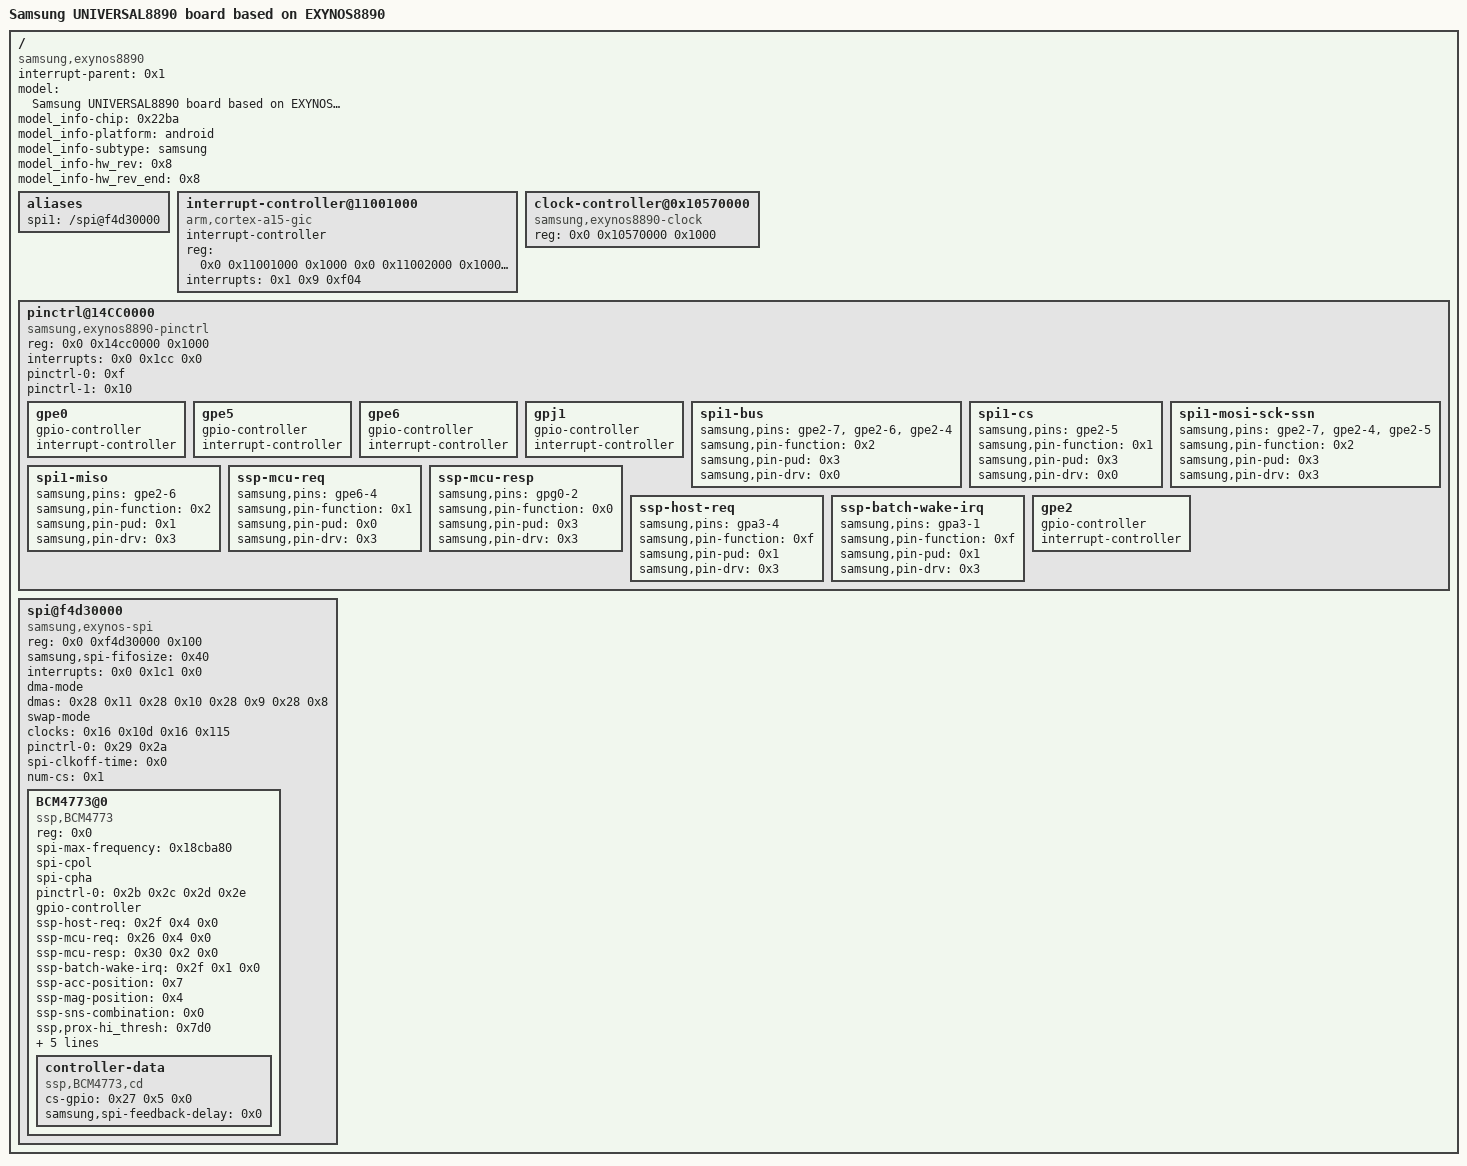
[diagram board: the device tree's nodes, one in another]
/dts-v1/;

/ {
        compatible = "samsung,exynos8890", "samsung,UNIVERSAL8890";
	interrupt-parent = <0x1>;
	#address-cells = <0x2>;
	#size-cells = <0x1>;
	model = "Samsung UNIVERSAL8890 board based on EXYNOS8890";
	model_info-chip = <0x22ba>;
	model_info-platform = "android";
	model_info-subtype = "samsung";
	model_info-hw_rev = <0x8>;
	model_info-hw_rev_end = <0x8>;

	aliases {
		//spi1 = "/spi@14d30000";
		spi1 = "/spi@f4d30000";
	};

	interrupt-controller@11001000 {
		compatible = "arm,cortex-a15-gic", "arm,cortex-a9-gic";
		#interrupt-cells = <0x3>;
		#address-cells = <0x0>;
		interrupt-controller;
		reg = <0x0 0x11001000 0x1000 0x0 0x11002000 0x1000 0x0 0x11004000 0x2000 0x0 0x11006000 0x2000>;
		interrupts = <0x1 0x9 0xf04>;
		linux,phandle = <0x1>;
		phandle = <0x1>;
	};

	clock-controller@0x10570000 {
		compatible = "samsung,exynos8890-clock";
		reg = <0x0 0x10570000 0x1000>;
		#clock-cells = <0x1>;
		linux,phandle = <0x16>;
		phandle = <0x16>;
	};

	pinctrl@14CC0000 {
		compatible = "samsung,exynos8890-pinctrl";
		reg = <0x0 0x14cc0000 0x1000>;
		interrupts = <0x0 0x1cc 0x0>;
		pinctrl-names = "default", "sleep";
		pinctrl-0 = <0xf>;
		pinctrl-1 = <0x10>;

		gpe0 {
			gpio-controller;
			#gpio-cells = <0x2>;
			interrupt-controller;
			#interrupt-cells = <0x2>;
		};

		gpe5 {
			gpio-controller;
			#gpio-cells = <0x2>;
			interrupt-controller;
			#interrupt-cells = <0x2>;
			linux,phandle = <0x5b>;
			phandle = <0x5b>;
		};

		gpe6 {
			gpio-controller;
			#gpio-cells = <0x2>;
			interrupt-controller;
			#interrupt-cells = <0x2>;
			linux,phandle = <0x26>;
			phandle = <0x26>;
		};

		gpj1 {
			gpio-controller;
			#gpio-cells = <0x2>;
			interrupt-controller;
			#interrupt-cells = <0x2>;
			linux,phandle = <0x96>;
			phandle = <0x96>;
		};

		spi1-bus {
			samsung,pins = "gpe2-7", "gpe2-6", "gpe2-4";
			samsung,pin-function = <0x2>;
			samsung,pin-pud = <0x3>;
			samsung,pin-drv = <0x0>;
		};

		spi1-cs {
			samsung,pins = "gpe2-5";
			samsung,pin-function = <0x1>;
			samsung,pin-pud = <0x3>;
			samsung,pin-drv = <0x0>;
		};

		spi1-mosi-sck-ssn {
			samsung,pins = "gpe2-7", "gpe2-4", "gpe2-5";
			samsung,pin-function = <0x2>;
			samsung,pin-pud = <0x3>;
			samsung,pin-drv = <0x3>;
			linux,phandle = <0x29>;
			phandle = <0x29>;
		};
	
		spi1-miso {
			samsung,pins = "gpe2-6";
			samsung,pin-function = <0x2>;
			samsung,pin-pud = <0x1>;
			samsung,pin-drv = <0x3>;
			linux,phandle = <0x2a>;
			phandle = <0x2a>;
		};

		ssp-mcu-req {
			samsung,pins = "gpe6-4";
			samsung,pin-function = <0x1>;
			samsung,pin-pud = <0x0>;
			samsung,pin-drv = <0x3>;
			linux,phandle = <0x2c>;
			phandle = <0x2c>;
		};

		ssp-mcu-resp {
			samsung,pins = "gpg0-2";
			samsung,pin-function = <0x0>;
			samsung,pin-pud = <0x3>;
			samsung,pin-drv = <0x3>;
			linux,phandle = <0x2d>;
			phandle = <0x2d>;
		};

		ssp-host-req {
			samsung,pins = "gpa3-4";
			samsung,pin-function = <0xf>;
			samsung,pin-pud = <0x1>;
			samsung,pin-drv = <0x3>;
			linux,phandle = <0x2b>;
			phandle = <0x2b>;
		};

		ssp-batch-wake-irq {
			samsung,pins = "gpa3-1";
			samsung,pin-function = <0xf>;
			samsung,pin-pud = <0x1>;
			samsung,pin-drv = <0x3>;
			linux,phandle = <0x2e>;
			phandle = <0x2e>;
		};

		gpe2 {
			gpio-controller;
			#gpio-cells = <0x2>;
			interrupt-controller;
			#interrupt-cells = <0x2>;
			linux,phandle = <0x27>;
			phandle = <0x27>;
		};
	};

	//spi@14d30000 {
	spi@f4d30000 {
		compatible = "samsung,exynos-spi";
		//reg = <0x0 0x14d30000 0x100>;
		reg = <0x0 0xf4d30000 0x100>;
		samsung,spi-fifosize = <0x40>;
		interrupts = <0x0 0x1c1 0x0>;
		////check-fusing-bit; //Ardalan: not supported
		dma-mode;
		dmas = <0x28 0x11 0x28 0x10 0x28 0x9 0x28 0x8>;
		dma-names = "tx", "rx", "tx-s", "rx-s";
		swap-mode;
		#address-cells = <0x1>;
		#size-cells = <0x0>;
		clocks = <0x16 0x10d 0x16 0x115>;
		clock-names = "spi", "spi_busclk0";
		pinctrl-names = "default";
		pinctrl-0 = <0x29 0x2a>;
		status = "okay";
		spi-clkoff-time = <0x0>;
		num-cs = <0x1>;

		BCM4773@0 {
			compatible = "ssp,BCM4773";
			reg = <0x0>;
			spi-max-frequency = <0x18cba80>;
			spi-cpol;
			spi-cpha;
			pinctrl-names = "default";
			pinctrl-0 = <0x2b 0x2c 0x2d 0x2e>;
			gpio-controller;
			#gpio-cells = <0x2>;
			ssp-host-req = <0x2f 0x4 0x0>;
			ssp-mcu-req = <0x26 0x4 0x0>;
			ssp-mcu-resp = <0x30 0x2 0x0>;
			ssp-batch-wake-irq = <0x2f 0x1 0x0>;
			ssp-acc-position = <0x7>;
			ssp-mag-position = <0x4>;
			ssp-sns-combination = <0x0>;
			ssp,prox-hi_thresh = <0x7d0>;
			ssp,prox-low_thresh = <0x578>;
			ssp-ap-rev = <0x1>;
			ssp-mag-array = <0x263b 0x296 0x4f 0x122 0x24f4 0x1b 0xc8 0xffffffdf 0x2988>;
			ssp-glass-type = <0x0>;

			controller-data {
				//Ardalan
				compatible = "ssp,BCM4773,cd";
				cs-gpio = <0x27 0x5 0x0>;
				samsung,spi-feedback-delay = <0x0>;
			};
		};
	};

};
